# RZT2ME register map
Vendor: Renesas Electronics Corporation; Series: RZT; File version: 1.00.00
CPU: other r0p0, little endian, MPU, no FPU, VTOR, 4 interrupt priority bits, 624 interrupts
Registers are 32-bit, read-write, reset 0x0 unless marked. A register's access mark holds for its fields unless they carry their own. Offsets are from the block's base; [hi:lo] are bit positions; {n}, {i} and the like mark numbered series; 'fields as' and 'values as' point back to an identical list.

## CMTW0 — Compare Match Timer W
Base 0x80041000
Same registers: CMTW1 0x80041400
0x00 CMWSTR 16-bit — Timer Start Register
  [0] STR — Counter Start
    0=The CMWCNT counter stops counting. The value immediately before a stop of counting is retained and counting is stopped.; 1=The CMWCNT counter starts counting
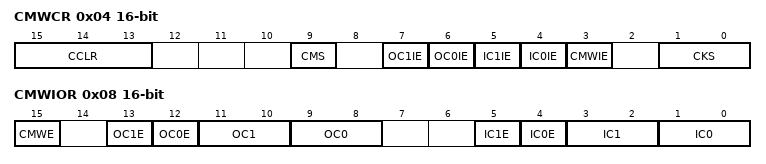
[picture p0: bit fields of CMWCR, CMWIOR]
0x04 CMWCR 16-bit — Timer Control Register
  [15:13] CCLR — Counter Clear
    0=The CMWCNT counter is cleared by CMWCOR register compare match; 1=The CMWCNT counter is not cleared; 2=The CMWCNT counter is not cleared; 3=The CMWCNT counter is not cleared; 4=The CMWCNT counter is cleared by CMWICR0 register input capture; 5=The CMWCNT counter is cleared by CMWICR1 register input capture; 6=The CMWCNT counter is cleared by CMWOCR0 register compare match; 7=The CMWCNT counter is cleared by CMWOCR1 register compare match
  [9] CMS — Timer Counter Size
    0=32 bits; 1=16 bits
  [7] OC1IE — Output Compare 1 Interrupt Enable
    0=Disables an interrupt request by the output compare 1 (CMTWm_OC1I); 1=Enables an interrupt request by the output compare 1 (CMTWm_OC1I)
  [6] OC0IE — Output Compare 0 Interrupt Enable
    0=Disables an interrupt request by the output compare 0 (CMTWm_OC0I); 1=Enables an interrupt request by the output compare 0 (CMTWm_OC0I)
  [5] IC1IE — Input Capture 1 Interrupt Enable
    0=Disables an interrupt request by the input capture 1 (CMTWm_IC1I); 1=Enables an interrupt request by the input capture 1 (CMTWm_IC1I)
  [4] IC0IE — Input Capture 0 Interrupt Enable
    0=Disables an interrupt request by the input capture 0 (CMTWm_IC0I); 1=Enables an interrupt request by the input capture 0 (CMTWm_IC0I)
  [3] CMWIE — Compare Match Interrupt Enable
    0=Disables a compare match interrupt request (CMTWm_CMWI); 1=Enables a compare match interrupt request (CMTWm_CMWI)
  [1:0] CKS — Clock Select
    0=PCLKL/8; 1=PCLKL/32; 2=PCLKL/128; 3=PCLKL/512
0x08 CMWIOR 16-bit — Timer I/O Control Register
  [15] CMWE — Compare Match Enable
    0=Disables the compare match operation using the CMWCOR register; 1=Enables the compare match operation using the CMWCOR register
  [13] OC1E — Compare Match Enable 1
    0=Disables the compare match operation using the CMWOCR1 register; 1=Enables the compare match operation using the CMWOCR1 register
  [12] OC0E — Compare Match Enable 0
    0=Disables the compare match operation using the CMWOCR0 register; 1=Enables the compare match operation using the CMWOCR0 register
  [11:10] OC1 — Output Compare Control 1
    0=Retains the output value; 1=Initially outputs 0 and toggles the output value upon compare match; 2=Initially outputs 1 and toggles the output value upon compare match; 3=Setting prohibited
  [9:8] OC0 — Output Compare Control 0
    values as OC1
  [5] IC1E — Input Capture Enable 1
    0=Disables the input capture operation of the CMWICR1 register; 1=Enables the input capture operation of the CMWICR1 register
  [4] IC0E — Input Capture Enable 0
    0=Disables the input capture operation of the CMWICR0 register; 1=Enables the input capture operation of the CMWICR0 register
  [3:2] IC1 — Input Capture Control 1
    0=Input capture at the rising edge on the TIC1 pin; 1=Input capture at the falling edge on the TIC1 pin; 2=Input capture at both edges on the TIC1 pin; 3=Setting prohibited
  [1:0] IC0 — Input Capture Control 0
    0=Input capture at the rising edge on the TIC0 pin; 1=Input capture at the falling edge on the TIC0 pin; 2=Input capture at both edges on the TIC0 pin; 3=Setting prohibited
0x10 CMWCNT — Timer Counter
0x14 CMWCOR reset 0xFFFFFFFF — Compare Match Constant Register
{0x18+4i} CMWICR{i} (i=0..1) ro — Input Capture Registers
{0x20+4i} CMWOCR{i} (i=0..1) reset 0xFFFFFFFF — Output Compare Registers
